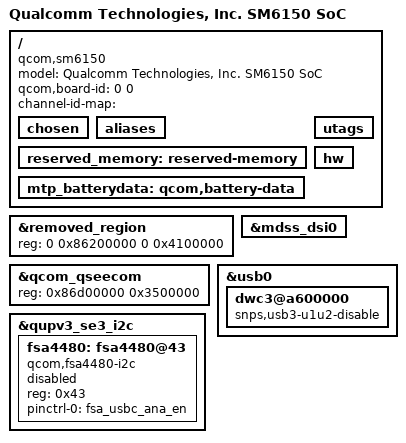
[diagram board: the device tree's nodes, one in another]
/* Copyright (c) 2018, The Linux Foundation. All rights reserved.
 *
 * This program is free software; you can redistribute it and/or modify
 * it under the terms of the GNU General Public License version 2 and
 * only version 2 as published by the Free Software Foundation.
 *
 * This program is distributed in the hope that it will be useful,
 * but WITHOUT ANY WARRANTY; without even the implied warranty of
 * MERCHANTABILITY or FITNESS FOR A PARTICULAR PURPOSE.  See the
 * GNU General Public License for more details.
 */

/dts-v1/;

#include "../sm6150.dtsi"
#include "../sm6150-audio.dtsi"

/ {
	model = "Qualcomm Technologies, Inc. SM6150 SoC";
	compatible = "qcom,sm6150";
	qcom,board-id = <0 0>;
	channel-id-map = "";
/*
 * Some nodes need labels assigned to appear in __symbols__
 */
	chosen: chosen { };
	aliases: aliases { };
	reserved_memory: reserved-memory { };
	mtp_batterydata: qcom,battery-data {};
	utags: utags { };
	hw: hw { };
};

&removed_region {
	reg = <0 0x86200000 0 0x4100000>;
};

&qcom_qseecom {
	reg = <0x86d00000 0x3500000>;
};

&mdss_dsi0 {
	/delete-property/ qcom,split-link-supported;
};

&usb0 {
	dwc3@a600000 {
		snps,usb3-u1u2-disable;
	};
};

&qupv3_se3_i2c {
        status = "ok";
        #include "../smb1390.dtsi"

        fsa4480: fsa4480@43 {
                compatible = "qcom,fsa4480-i2c";
                reg = <0x43>;
                pinctrl-names = "default";
                pinctrl-0 = <&fsa_usbc_ana_en>;
                status = "disabled";
        };
};
